# RA2A1 register map
Vendor: Renesas Electronics Corporation; Series: RA2; File version: 1.1
CPU: other r1p0, little endian, MPU, no FPU, VTOR, 2 interrupt priority bits
Registers are 8-bit, read-write, reset 0x0 unless marked. A register's access mark holds for its fields unless they carry their own. Offsets are from the block's base; [hi:lo] are bit positions.

## DBG — Debug Function
Base 0x4001B000
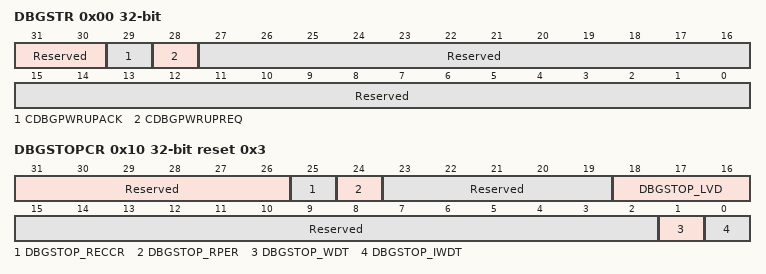
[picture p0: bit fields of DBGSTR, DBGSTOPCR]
0x00 DBGSTR 32-bit ro — Debug Status Register
  [31:30] Reserved — These bits are read as 00.
  [29] CDBGPWRUPACK — Debug power-up acknowledge
    0=Debug power-up request is not acknowledged; 1=Debug power-up request is acknowledged
  [28] CDBGPWRUPREQ — Debug power-up request
    0=OCD is not requesting debug power-up; 1=OCD is requesting debug power-up
  [27:0] Reserved — These bits are read as 0000000000000000000000000000.
0x10 DBGSTOPCR 32-bit reset 0x3 — Debug Stop Control Register
  [31:26] Reserved — These bits are read as 000000. The write value should be 000000.
  [25] DBGSTOP_RECCR — Mask bit for SRAM ECC error reset/interrupt
    0=Enable SRAM ECC error reset/interrupt; 1=Mask SRAM ECC error reset/interrupt
  [24] DBGSTOP_RPER — Mask bit for RAM parity error reset/interrupt
    0=Enable RAM parity error reset/interrupt; 1=Mask RAM parity error reset/interrupt
  [23:19] Reserved — These bits are read as 00000. The write value should be 00000.
  [18:16] DBGSTOP_LVD — b18: Mask bit for LVD2 reset/interrupt (0:enable / 1:Mask)b17: Mask bit for LVD1 reset/interrupt (0:enable / 1:Mask)b16: Mask bit for LVD0 reset (0:enable / 1:Mask)
  [15:2] Reserved — These bits are read as 00000000000000. The write value should be 00000000000000.
  [1] DBGSTOP_WDT — Mask bit for WDT reset/interrupt
    0=Mask WDT reset/interrupt; 1=Enable WDT reset
  [0] DBGSTOP_IWDT — Mask bit for IWDT reset/interrupt
    0=Mask IWDT reset/interrupt; 1=Enable IWDT reset

## DTC — Data Transfer Controller
Base 0x40005400
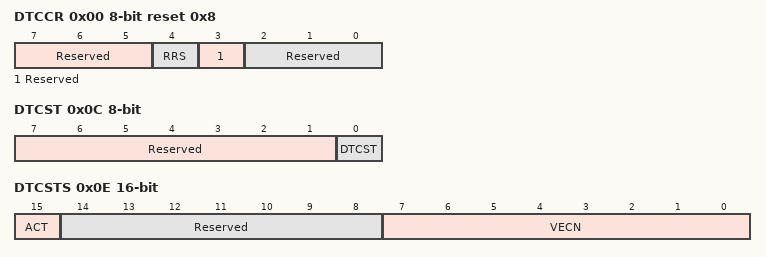
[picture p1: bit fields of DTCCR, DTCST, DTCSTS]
0x00 DTCCR reset 0x8 — DTC Control Register
  [7:5] Reserved — These bits are read as 000. The write value should be 000.
  [4] RRS — DTC Transfer Information Read Skip Enable.
    0=Do not skip transfer information read; 1=Skip transfer information read when vector numbers match
  [3] Reserved — This bit is read as 1. The write value should be 1.
  [2:0] Reserved — These bits are read as 000. The write value should be 000.
0x04 DTCVBR 32-bit — DTC Vector Base Register
  [31:0] DTCVBR — DTC Vector Base Address.Note: A value cannot be set in the lower-order 10 bits. These bits are fixed to 0.
0x0C DTCST — DTC Module Start Register
  [7:1] Reserved — These bits are read as 0000000. The write value should be 0000000.
  [0] DTCST — DTC Module Start
    0=DTC module stop; 1=DTC module start
0x0E DTCSTS 16-bit ro — DTC Status Register
  [15] ACT — DTC Active Flag
    0=DTC transfer operation is not in progress; 1=DTC transfer operation is in progress
  [14:8] Reserved — These bits are read as 0000000.
  [7:0] VECN — DTC-Activating Vector Number MonitoringThese bits indicate the vector number for the activating source when DTC transfer is in progress.The value is only valid if DTC transfer is in progress (the value of the ACT flag is 1)

## GPT_OPS — Output Phase Switching Controller
Base 0x40078FF0
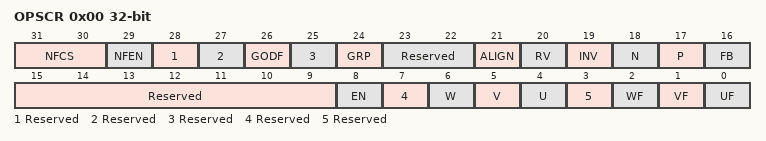
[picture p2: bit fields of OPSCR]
0x00 OPSCR 32-bit — Output Phase Switching Control Register
  [31:30] NFCS — External Input Noise Filter Clock selectionNoise filter sampling clock setting of the external input.
    0=PCLK/1; 1=PCLK/4; 2=PCLK/16; 3=PCLK/64
  [29] NFEN — External Input Noise Filter Enable
    0=Do not use a noise filter to the external input; 1=Use a noise filter to the external input
  [28] Reserved — This bit is read as 0. The write value should be 0.
  [27] Reserved — This bit is read as 0. The write value should be 0.
  [26] GODF — Group output disable function
    0=This bit function is ignored; 1=Group disable will clear OPSCR.EN Bit
  [25] Reserved — This bit is read as 0. The write value should be 0.
  [24] GRP — Output disabled source selection
    0=Select Group A output disable source; 1=Select Group B output disable source
  [23:22] Reserved — These bits are read as 00. The write value should be 00.
  [21] ALIGN — Input phase alignment
    0=Input phase is aligned to PCLK; 1=Input phase is aligned PWM
  [20] RV — Output phase rotation direction reversal
    0=U/V/W-Phase output; 1=Output to reverse the V / W-phase
  [19] INV — Invert-Phase Output Control
    0=Positive Logic (Active High)output; 1=Negative Logic (Active Low)output
  [18] N — Negative-Phase Output (N) Control
    0=Level signal output; 1=PWM signal output (PWM of GPT0)
  [17] P — Positive-Phase Output (P) Control
    0=Level signal output; 1=PWM signal output (PWM of GPT0)
  [16] FB — External Feedback Signal EnableThis bit selects the input phase from the software settings and external input.
    0=Select the external input; 1=Select the soft setting(OPSCR.UF, VF, WF)
  [15:9] Reserved — These bits are read as 0000000. The write value should be 0000000.
  [8] EN — Enable-Phase Output Control
    0=Not Output(Hi-Z external terminals); 1=Output
  [7] Reserved — This bit is read as 0. The write value should be 0.
  [6] W ro — Input W-Phase MonitorThis bit monitors the state of the input phase.OPSCR.FB=0:External input monitoring by PCLKOPSCR.FB=1:Software settings (UF/VF/WF)
  [5] V ro — Input V-Phase MonitorThis bit monitors the state of the input phase.OPSCR.FB=0:External input monitoring by PCLKOPSCR.FB=1:Software settings (UF/VF/WF)
  [4] U ro — Input U-Phase MonitorThis bit monitors the state of the input phase.OPSCR.FB=0:External input monitoring by PCLKOPSCR.FB=1:Software settings (UF/VF/WF)
  [3] Reserved — This bit is read as 0. The write value should be 0.
  [2] WF — Input Phase Soft Setting UFThis bit sets the input phase by the software settings.This bit setting is valid when the OPSCR.FB bit = 1.
  [1] VF — Input Phase Soft Setting VFThis bit sets the input phase by the software settings.This bit setting is valid when the OPSCR.FB bit = 1.
  [0] UF — Input Phase Soft Setting WFThis bit sets the input phase by the software settings.This bit setting is valid when the OPSCR.FB bit = 1.
